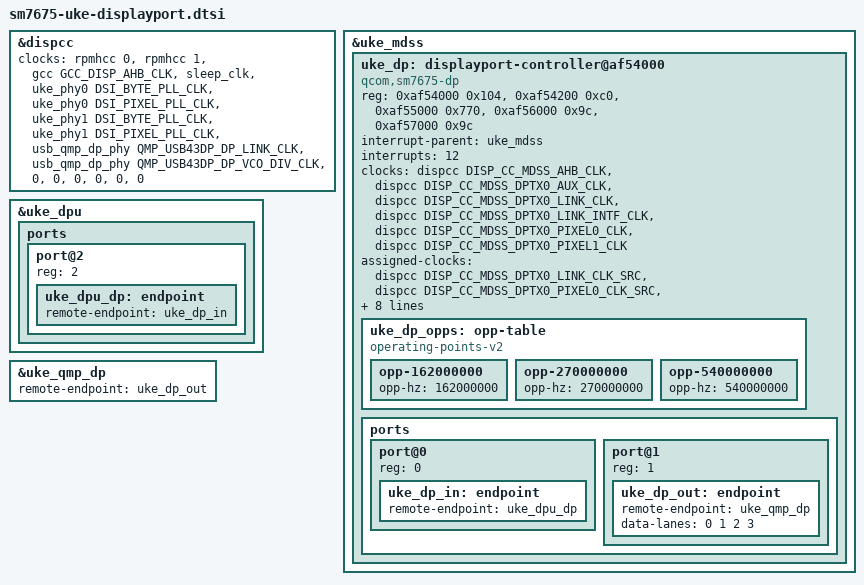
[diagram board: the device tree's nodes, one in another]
// SPDX-License-Identifier: GPL-2.0-only OR BSD-2-Clause
/* Exact Uke MMIO/IRQ and HBR2 ceiling; upstream SM8650 describes shared IP. */
#include <dt-bindings/phy/phy-qcom-qmp.h>

&dispcc {
	clocks = <&rpmhcc 0>, <&rpmhcc 1>, <&gcc GCC_DISP_AHB_CLK>, <&sleep_clk>,
		 <&uke_phy0 DSI_BYTE_PLL_CLK>, <&uke_phy0 DSI_PIXEL_PLL_CLK>,
		 <&uke_phy1 DSI_BYTE_PLL_CLK>, <&uke_phy1 DSI_PIXEL_PLL_CLK>,
		 <&usb_qmp_dp_phy QMP_USB43DP_DP_LINK_CLK>,
		 <&usb_qmp_dp_phy QMP_USB43DP_DP_VCO_DIV_CLK>,
		 <0>, <0>, <0>, <0>, <0>, <0>;
};

&uke_mdss {
	uke_dp: displayport-controller@af54000 {
		compatible = "qcom,sm7675-dp";
		reg = <0xaf54000 0x104>, <0xaf54200 0xc0>, <0xaf55000 0x770>,
		      <0xaf56000 0x9c>, <0xaf57000 0x9c>;
		interrupt-parent = <&uke_mdss>;
		interrupts = <12>;
		clocks = <&dispcc DISP_CC_MDSS_AHB_CLK>,
			 <&dispcc DISP_CC_MDSS_DPTX0_AUX_CLK>,
			 <&dispcc DISP_CC_MDSS_DPTX0_LINK_CLK>,
			 <&dispcc DISP_CC_MDSS_DPTX0_LINK_INTF_CLK>,
			 <&dispcc DISP_CC_MDSS_DPTX0_PIXEL0_CLK>,
			 <&dispcc DISP_CC_MDSS_DPTX0_PIXEL1_CLK>;
		clock-names = "core_iface", "core_aux", "ctrl_link", "ctrl_link_iface",
			      "stream_pixel", "stream_1_pixel";
		assigned-clocks = <&dispcc DISP_CC_MDSS_DPTX0_LINK_CLK_SRC>,
				  <&dispcc DISP_CC_MDSS_DPTX0_PIXEL0_CLK_SRC>,
				  <&dispcc DISP_CC_MDSS_DPTX0_PIXEL1_CLK_SRC>;
		assigned-clock-parents = <&usb_qmp_dp_phy QMP_USB43DP_DP_LINK_CLK>,
					 <&usb_qmp_dp_phy QMP_USB43DP_DP_VCO_DIV_CLK>,
					 <&usb_qmp_dp_phy QMP_USB43DP_DP_VCO_DIV_CLK>;
		phys = <&usb_qmp_dp_phy QMP_USB43DP_DP_PHY>;
		phy-names = "dp";
		operating-points-v2 = <&uke_dp_opps>;
		#sound-dai-cells = <0>;
		sound-name-prefix = "DisplayPort0";
		status = "okay";
		uke_dp_opps: opp-table {
			compatible = "operating-points-v2";
			opp-162000000 { opp-hz = /bits/ 64 <162000000>; };
			opp-270000000 { opp-hz = /bits/ 64 <270000000>; };
			opp-540000000 { opp-hz = /bits/ 64 <540000000>; };
		};
		ports {
			#address-cells = <1>;
			#size-cells = <0>;
			port@0 { reg = <0>; uke_dp_in: endpoint { remote-endpoint = <&uke_dpu_dp>; }; };
			port@1 { reg = <1>; uke_dp_out: endpoint { remote-endpoint = <&uke_qmp_dp>; data-lanes = <0 1 2 3>; }; };
		};
	};
};

&uke_dpu {
	ports {
		port@2 { reg = <2>; uke_dpu_dp: endpoint { remote-endpoint = <&uke_dp_in>; }; };
	};
};

&uke_qmp_dp { remote-endpoint = <&uke_dp_out>; };
